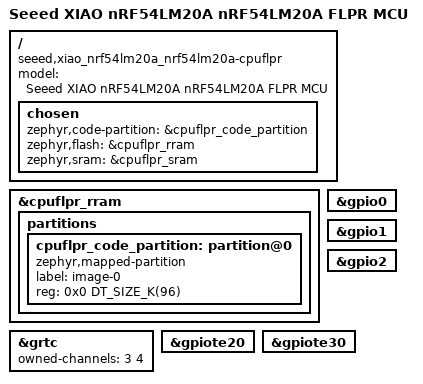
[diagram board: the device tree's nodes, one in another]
/*
 * Copyright (c) 2025 Seeed Technology Co., Ltd.
 *
 * SPDX-License-Identifier: Apache-2.0
 */

/dts-v1/;
#include <nordic/nrf54lm20_a_b_cpuflpr.dtsi>
#include "xiao_nrf54lm20a_nrf54lm20a-common.dtsi"

/ {
	model = "Seeed XIAO nRF54LM20A nRF54LM20A FLPR MCU";
	compatible = "seeed,xiao_nrf54lm20a_nrf54lm20a-cpuflpr";

	chosen {
		zephyr,code-partition = &cpuflpr_code_partition;
		zephyr,flash = &cpuflpr_rram;
		zephyr,sram = &cpuflpr_sram;
	};
};

&cpuflpr_rram {
	partitions {
		#address-cells = <1>;
		#size-cells = <1>;
		ranges;

		cpuflpr_code_partition: partition@0 {
			compatible = "zephyr,mapped-partition";
			label = "image-0";
			reg = <0x0 DT_SIZE_K(96)>;
		};
	};
};

&grtc {
	owned-channels = <3 4>;
	status = "okay";
};

&gpio0 {
	status = "okay";
};

&gpio1 {
	status = "okay";
};

&gpio2 {
	status = "okay";
};

&gpiote20 {
	status = "okay";
};

&gpiote30 {
	status = "okay";
};
